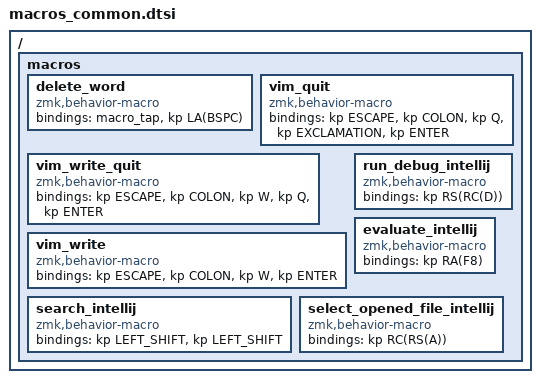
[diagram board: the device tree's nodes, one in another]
/ {
    macros {

    delete_word: delete_word {
        compatible = "zmk,behavior-macro";
        #binding-cells = <0>;
        bindings = 
        <&macro_tap &kp LA(BSPC)>;
    };

// ┌─────┬─────┬─────┬─────┬─────┐  ┌─────┬─────┬─────┬─────┬─────┐
// │  Q  │     │     │     │     │  │     │     │     │     │     │
// │─────┼─────┼─────┼─────┼─────┤  │─────┼─────┼─────┼─────┼─────┤
// │     │     │     │     │     │  │     │     │     │     │     │
// │─────┼─────┼─────┼─────┼─────┤  │─────┼─────┼─────┼─────┼─────┤
// │     │     │     │     │     │  │     │     │     │     │     │
// └─────┴─────┴─────┼─────┤─────┤  │─────┼─────┼─────┴─────┴─────┘ 
//                   │     │     │  │ [v] │     │
//                   └─────┴─────┘  └─────┴─────┘

        vim_quit: vim_quit {
            compatible = "zmk,behavior-macro";
            #binding-cells = <0>;
            bindings = <&kp ESCAPE &kp COLON &kp Q &kp EXCLAMATION &kp ENTER>;

        };

// ┌─────┬─────┬─────┬─────┬─────┐  ┌─────┬─────┬─────┬─────┬─────┐
// │     │  W  │     │     │     │  │     │     │     │     │     │
// │─────┼─────┼─────┼─────┼─────┤  │─────┼─────┼─────┼─────┼─────┤
// │     │     │     │     │     │  │     │     │     │     │     │
// │─────┼─────┼─────┼─────┼─────┤  │─────┼─────┼─────┼─────┼─────┤
// │     │     │     │     │     │  │     │     │     │     │     │
// └─────┴─────┴─────┼─────┤─────┤  │─────┼─────┼─────┴─────┴─────┘ 
//                   │     │     │  │ [v] │     │
//                   └─────┴─────┘  └─────┴─────┘


        vim_write_quit: vim_write_quit {
            compatible = "zmk,behavior-macro";
            #binding-cells = <0>;
            bindings = <&kp ESCAPE &kp COLON &kp W &kp Q &kp ENTER>;
        };

// ┌─────┬─────┬─────┬─────┬─────┐  ┌─────┬─────┬─────┬─────┬─────┐
// │     │     │     │     │     │  │     │     │     │     │     │
// │─────┼─────┼─────┼─────┼─────┤  │─────┼─────┼─────┼─────┼─────┤
// │     │ [x] │     │     │     │  │     │     │     │     │     │
// │─────┼─────┼─────┼─────┼─────┤  │─────┼─────┼─────┼─────┼─────┤
// │     │     │     │     │     │  │     │     │     │     │     │
// └─────┴─────┴─────┼─────┤─────┤  │─────┼─────┼─────┴─────┴─────┘ 
//                   │     │     │  │ [v] │     │
//                   └─────┴─────┘  └─────┴─────┘


        vim_write: vim_write {
            compatible = "zmk,behavior-macro";
            #binding-cells = <0>;
            bindings = <&kp ESCAPE &kp COLON &kp W &kp ENTER>;
        };

// ┌─────┬─────┬─────┬─────┬─────┐  ┌─────┬─────┬─────┬─────┬─────┐
// │     │     │     │     │     │  │     │     │     │     │     │
// │─────┼─────┼─────┼─────┼─────┤  │─────┼─────┼─────┼─────┼─────┤
// │     │     │     │     │     │  │     │     │     │     │     │
// │─────┼─────┼─────┼─────┼─────┤  │─────┼─────┼─────┼─────┼─────┤
// │     │     │     │     │     │  │  K  │     │     │     │     │
// └─────┴─────┴─────┼─────┤─────┤  │─────┼─────┼─────┴─────┴─────┘ 
//                   │     │     │  │ [v] │ [v] │
//                   └─────┴─────┘  └─────┴─────┘

        search_intellij: search_intellij {
            compatible = "zmk,behavior-macro";
            #binding-cells = <0>;
            bindings = <&kp LEFT_SHIFT &kp LEFT_SHIFT>;
        };

// ┌─────┬─────┬─────┬─────┬─────┐  ┌─────┬─────┬─────┬─────┬─────┐
// │     │     │     │     │     │  │     │     │     │     │     │
// │─────┼─────┼─────┼─────┼─────┤  │─────┼─────┼─────┼─────┼─────┤
// │     │     │     │     │     │  │     │  N  │     │     │     │
// │─────┼─────┼─────┼─────┼─────┤  │─────┼─────┼─────┼─────┼─────┤
// │     │     │     │     │     │  │     │     │     │     │     │
// └─────┴─────┴─────┼─────┤─────┤  │─────┼─────┼─────┴─────┴─────┘ 
//                   │     │     │  │ [v] │ [v] │
//                   └─────┴─────┘  └─────┴─────┘

        run_debug_intellij: run_debug_intellij {
            compatible = "zmk,behavior-macro";
            #binding-cells = <0>;
            bindings = <&kp RS(RC(D))>;
        };

// ┌─────┬─────┬─────┬─────┬─────┐  ┌─────┬─────┬─────┬─────┬─────┐
// │     │     │     │     │     │  │     │     │     │     │     │
// │─────┼─────┼─────┼─────┼─────┤  │─────┼─────┼─────┼─────┼─────┤
// │     │     │     │     │     │  │     │     │  E  │     │     │
// │─────┼─────┼─────┼─────┼─────┤  │─────┼─────┼─────┼─────┼─────┤
// │     │     │     │     │     │  │     │     │     │     │     │
// └─────┴─────┴─────┼─────┤─────┤  │─────┼─────┼─────┴─────┴─────┘ 
//                   │     │     │  │ [v] │ [v] │
//                   └─────┴─────┘  └─────┴─────┘

        evaluate_intellij: evaluate_intellij {
            compatible = "zmk,behavior-macro";
            #binding-cells = <0>;
            bindings = <&kp RA(F8)>;
        };

// ┌─────┬─────┬─────┬─────┬─────┐  ┌─────┬─────┬─────┬─────┬─────┐
// │     │     │     │     │     │  │     │     │     │     │     │
// │─────┼─────┼─────┼─────┼─────┤  │─────┼─────┼─────┼─────┼─────┤
// │     │     │     │     │     │  │     │     │     │     │     │
// │─────┼─────┼─────┼─────┼─────┤  │─────┼─────┼─────┼─────┼─────┤
// │     │     │     │     │     │  │     │     │     │  .  │     │
// └─────┴─────┴─────┼─────┤─────┤  │─────┼─────┼─────┴─────┴─────┘ 
//                   │     │     │  │ [v] │ [v] │
//                   └─────┴─────┘  └─────┴─────┘

        select_opened_file_intellij: select_opened_file_intellij {
            compatible = "zmk,behavior-macro";
            #binding-cells = <0>;
            bindings = <&kp RC(RS(A))>;
        };
    };

};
